# ESP32-C6-LP register map
Vendor: ESPRESSIF SYSTEMS (SHANGHAI) CO., LTD.; Series: ESP32 C-Series; File version: 3
CPU: RV32IMAC r0p0, little endian, no MPU, no FPU, 0 interrupt priority bits
Address unit: 32 bits
Registers are 32-bit, read-write, reset 0x0 unless marked. A register's access mark holds for its fields unless they carry their own. Offsets are from the block's base; [hi:lo] are bit positions; {n}, {i} and the like mark numbered series.

## LP_I2C_ANA_MST — LP_I2C_ANA_MST Peripheral
Base 0x600B2400
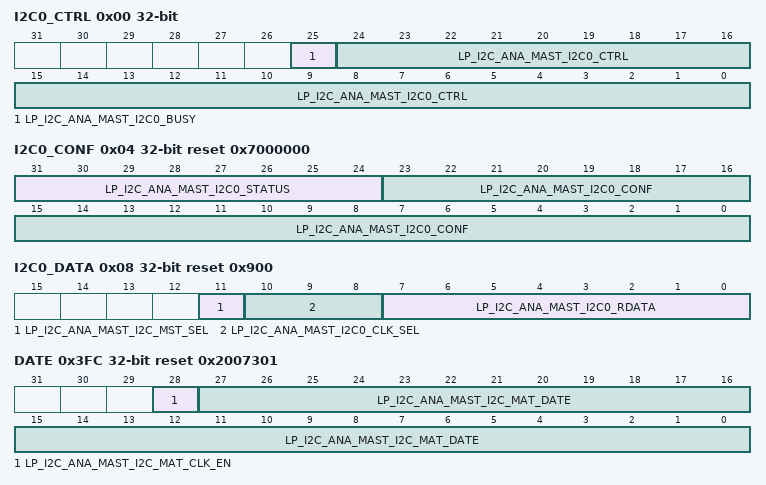
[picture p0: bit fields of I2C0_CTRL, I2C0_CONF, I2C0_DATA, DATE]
0x00 I2C0_CTRL access per field — need_des
  [25] LP_I2C_ANA_MAST_I2C0_BUSY ro — need_des
  [24:0] LP_I2C_ANA_MAST_I2C0_CTRL rw — need_des
0x04 I2C0_CONF access per field reset 0x7000000 — need_des
  [31:24] LP_I2C_ANA_MAST_I2C0_STATUS ro — reserved
  [23:0] LP_I2C_ANA_MAST_I2C0_CONF rw — need_des
0x08 I2C0_DATA access per field reset 0x900 — need_des
  [11] LP_I2C_ANA_MAST_I2C_MST_SEL rw — need des
  [10:8] LP_I2C_ANA_MAST_I2C0_CLK_SEL rw — need_des
  [7:0] LP_I2C_ANA_MAST_I2C0_RDATA ro — need_des
0x0C ANA_CONF1 — need_des
  [23:0] LP_I2C_ANA_MAST_ANA_CONF1
0x10 NOUSE — need_des
  [31:0] LP_I2C_ANA_MAST_I2C_MST_NOUSE
0x14 DEVICE_EN — need_des
  [11:0] LP_I2C_ANA_MAST_I2C_DEVICE_EN
0x3FC DATE reset 0x2007301 — need_des
  [28] LP_I2C_ANA_MAST_I2C_MAT_CLK_EN — need_des
  [27:0] LP_I2C_ANA_MAST_I2C_MAT_DATE — need_des

## LP_IO — LP_IO Peripheral
Base 0x600B2000
0x00 OUT — need des
  [7:0] OUT_DATA — set lp gpio output data
0x04 OUT_W1TS wo — need des
  [7:0] OUT_DATA_W1TS — set one time output data
0x08 OUT_W1TC wo — need des
  [7:0] OUT_DATA_W1TC — clear one time output data
0x0C ENABLE — need des
  [7:0] ENABLE — set lp gpio output data
0x10 ENABLE_W1TS wo — need des
  [7:0] ENABLE_W1TS — set one time output data
0x14 ENABLE_W1TC wo — need des
  [7:0] ENABLE_W1TC — clear one time output data
0x18 STATUS — need des
  [7:0] INTERRUPT — set lp gpio output data
0x1C STATUS_W1TS wo — need des
  [7:0] STATUS_W1TS — set one time output data
0x20 STATUS_W1TC wo — need des
  [7:0] STATUS_W1TC — clear one time output data
0x24 IN ro — need des
  [7:0] DATA_NEXT
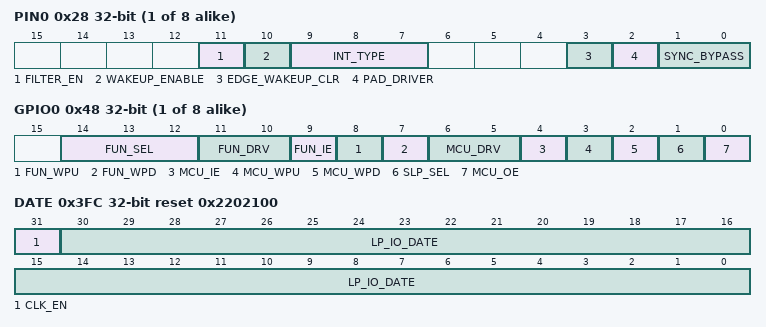
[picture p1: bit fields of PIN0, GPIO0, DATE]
{0x28+4i} PIN{i} (i=0..7) access per field — need des
  [11] FILTER_EN rw — need des
  [10] WAKEUP_ENABLE rw — need des
  [9:7] INT_TYPE rw — need des
  [3] EDGE_WAKEUP_CLR wo — need des
  [2] PAD_DRIVER rw — need des
  [1:0] SYNC_BYPASS rw — need des
{0x48+4i} GPIO{i} (i=0..7) — need des
  [14:12] FUN_SEL — need des
  [11:10] FUN_DRV — need des
  [9] FUN_IE — need des
  [8] FUN_WPU — need des
  [7] FUN_WPD — need des
  [6:5] MCU_DRV — need des
  [4] MCU_IE — need des
  [3] MCU_WPU — need des
  [2] MCU_WPD — need des
  [1] SLP_SEL — need des
  [0] MCU_OE — need des
0x68 STATUS_INT ro — need des
  [7:0] NEXT
0x3FC DATE reset 0x2202100 — need des
  [31] CLK_EN — need des
  [30:0] LP_IO_DATE — need des

## LP_TEE — Low-power Trusted Execution Environment
Base 0x600B3400
{0x0+4i} M{i}_MODE_CTRL (i=0..0) reset 0x3 — Tee mode control register
  [1:0] MODE — M0 security level mode: 2'd3: ree_mode2. 2'd2: ree_mode1. 2'd1: ree_mode0. 2'd0: tee_mode
    0=Tee (Tee mode); 1=Ree0 mode; 2=Ree1 mode; 3=Ree2 mode
0x04 CLOCK_GATE reset 0x1 — Clock gating register
  [0] CLK_EN — reg_clk_en
0x90 FORCE_ACC_HP — need_des
  [0] LP_AON_FORCE_ACC_HPMEM_EN
0xFC DATE reset 0x2205270 — Version register
  [27:0] DATE — reg_tee_date

## LP_TIMER — Low-power Timer
Base 0x600B0C00
0x00 TAR0_LOW — need_des
  [31:0] MAIN_TIMER_TAR_LOW0
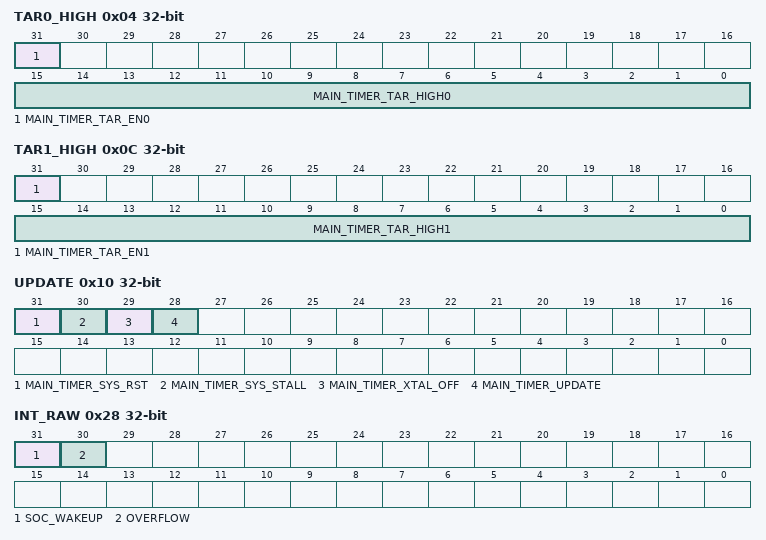
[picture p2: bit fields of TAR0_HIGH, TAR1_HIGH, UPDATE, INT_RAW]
0x04 TAR0_HIGH access per field — need_des
  [31] MAIN_TIMER_TAR_EN0 wo — need_des
  [15:0] MAIN_TIMER_TAR_HIGH0 rw — need_des
0x08 TAR1_LOW — need_des
  [31:0] MAIN_TIMER_TAR_LOW1
0x0C TAR1_HIGH access per field — need_des
  [31] MAIN_TIMER_TAR_EN1 wo — need_des
  [15:0] MAIN_TIMER_TAR_HIGH1 rw — need_des
0x10 UPDATE access per field — need_des
  [31] MAIN_TIMER_SYS_RST rw — need_des
  [30] MAIN_TIMER_SYS_STALL rw — need_des
  [29] MAIN_TIMER_XTAL_OFF rw — need_des
  [28] MAIN_TIMER_UPDATE wo — need_des
0x14 MAIN_BUF0_LOW ro — need_des
  [31:0] MAIN_TIMER_BUF0_LOW
0x18 MAIN_BUF0_HIGH ro — need_des
  [15:0] MAIN_TIMER_BUF0_HIGH
0x1C MAIN_BUF1_LOW ro — need_des
  [31:0] MAIN_TIMER_BUF1_LOW
0x20 MAIN_BUF1_HIGH ro — need_des
  [15:0] MAIN_TIMER_BUF1_HIGH
0x24 MAIN_OVERFLOW wo — need_des
  [31] MAIN_TIMER_ALARM_LOAD
0x28 INT_RAW — need_des
  [31] SOC_WAKEUP — need_des
  [30] OVERFLOW — need_des
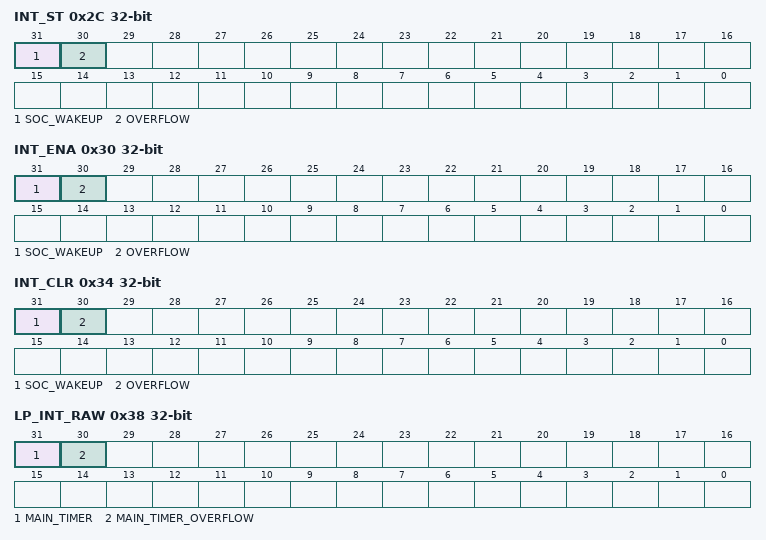
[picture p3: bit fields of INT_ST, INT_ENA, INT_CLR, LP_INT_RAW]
0x2C INT_ST ro — need_des
  [31] SOC_WAKEUP — need_des
  [30] OVERFLOW — need_des
0x30 INT_ENA — need_des
  [31] SOC_WAKEUP — need_des
  [30] OVERFLOW — need_des
0x34 INT_CLR wo — need_des
  [31] SOC_WAKEUP write-1-clears — need_des
  [30] OVERFLOW write-1-clears — need_des
0x38 LP_INT_RAW — need_des
  [31] MAIN_TIMER — need_des
  [30] MAIN_TIMER_OVERFLOW — need_des
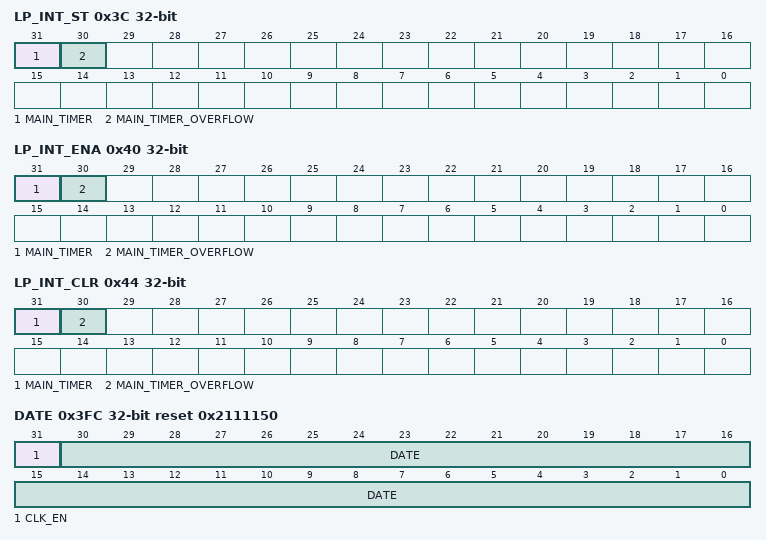
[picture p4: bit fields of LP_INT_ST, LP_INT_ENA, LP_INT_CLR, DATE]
0x3C LP_INT_ST ro — need_des
  [31] MAIN_TIMER — need_des
  [30] MAIN_TIMER_OVERFLOW — need_des
0x40 LP_INT_ENA — need_des
  [31] MAIN_TIMER — need_des
  [30] MAIN_TIMER_OVERFLOW — need_des
0x44 LP_INT_CLR wo — need_des
  [31] MAIN_TIMER write-1-clears — need_des
  [30] MAIN_TIMER_OVERFLOW write-1-clears — need_des
0x3FC DATE reset 0x2111150 — need_des
  [31] CLK_EN — need_des
  [30:0] DATE — need_des

## LP_WDT — Low-power Watchdog Timer
Base 0x600B1C00
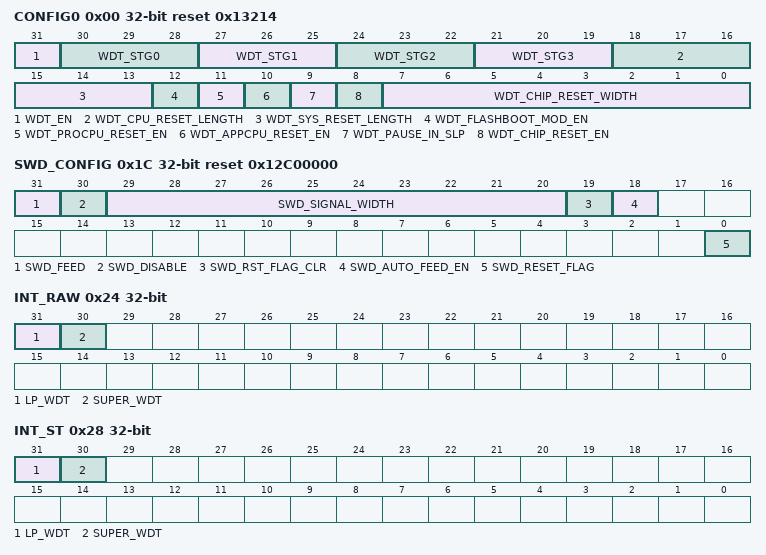
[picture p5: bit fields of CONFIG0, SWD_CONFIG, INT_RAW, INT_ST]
0x00 CONFIG0 reset 0x13214 — need_des
  [31] WDT_EN — need_des
  [30-3n:28-3n] WDT_STG{n} (n=0..3) — need_des
  [18:16] WDT_CPU_RESET_LENGTH — need_des
  [15:13] WDT_SYS_RESET_LENGTH — need_des
  [12] WDT_FLASHBOOT_MOD_EN — need_des
  [11] WDT_PROCPU_RESET_EN — need_des
  [10] WDT_APPCPU_RESET_EN — need_des
  [9] WDT_PAUSE_IN_SLP — need_des
  [8] WDT_CHIP_RESET_EN — need_des
  [7:0] WDT_CHIP_RESET_WIDTH — need_des
0x04 CONFIG1 reset 0x30D40 — need_des
  [31:0] WDT_STG0_HOLD
0x08 CONFIG2 reset 0x13880 — need_des
  [31:0] WDT_STG1_HOLD
0x0C CONFIG3 reset 0xFFF — need_des
  [31:0] WDT_STG2_HOLD
0x10 CONFIG4 reset 0xFFF — need_des
  [31:0] WDT_STG3_HOLD
0x14 FEED wo — need_des
  [31] RTC_WDT_FEED
0x18 WPROTECT — need_des
  [31:0] WDT_WKEY
0x1C SWD_CONFIG access per field reset 0x12C00000 — need_des
  [31] SWD_FEED wo — need_des
  [30] SWD_DISABLE rw — need_des
  [29:20] SWD_SIGNAL_WIDTH rw — need_des
  [19] SWD_RST_FLAG_CLR wo — need_des
  [18] SWD_AUTO_FEED_EN rw — need_des
  [0] SWD_RESET_FLAG ro — need_des
0x20 SWD_WPROTECT — need_des
  [31:0] SWD_WKEY
0x24 INT_RAW — need_des
  [31] LP_WDT — need_des
  [30] SUPER_WDT — need_des
0x28 INT_ST ro — need_des
  [31] LP_WDT — need_des
  [30] SUPER_WDT — need_des
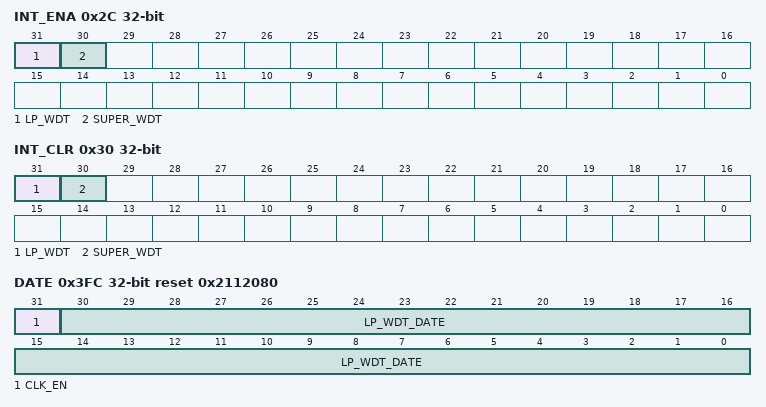
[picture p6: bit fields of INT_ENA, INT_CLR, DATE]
0x2C INT_ENA — need_des
  [31] LP_WDT — need_des
  [30] SUPER_WDT — need_des
0x30 INT_CLR wo — need_des
  [31] LP_WDT write-1-clears — need_des
  [30] SUPER_WDT write-1-clears — need_des
0x3FC DATE reset 0x2112080 — need_des
  [31] CLK_EN — need_des
  [30:0] LP_WDT_DATE — need_des
